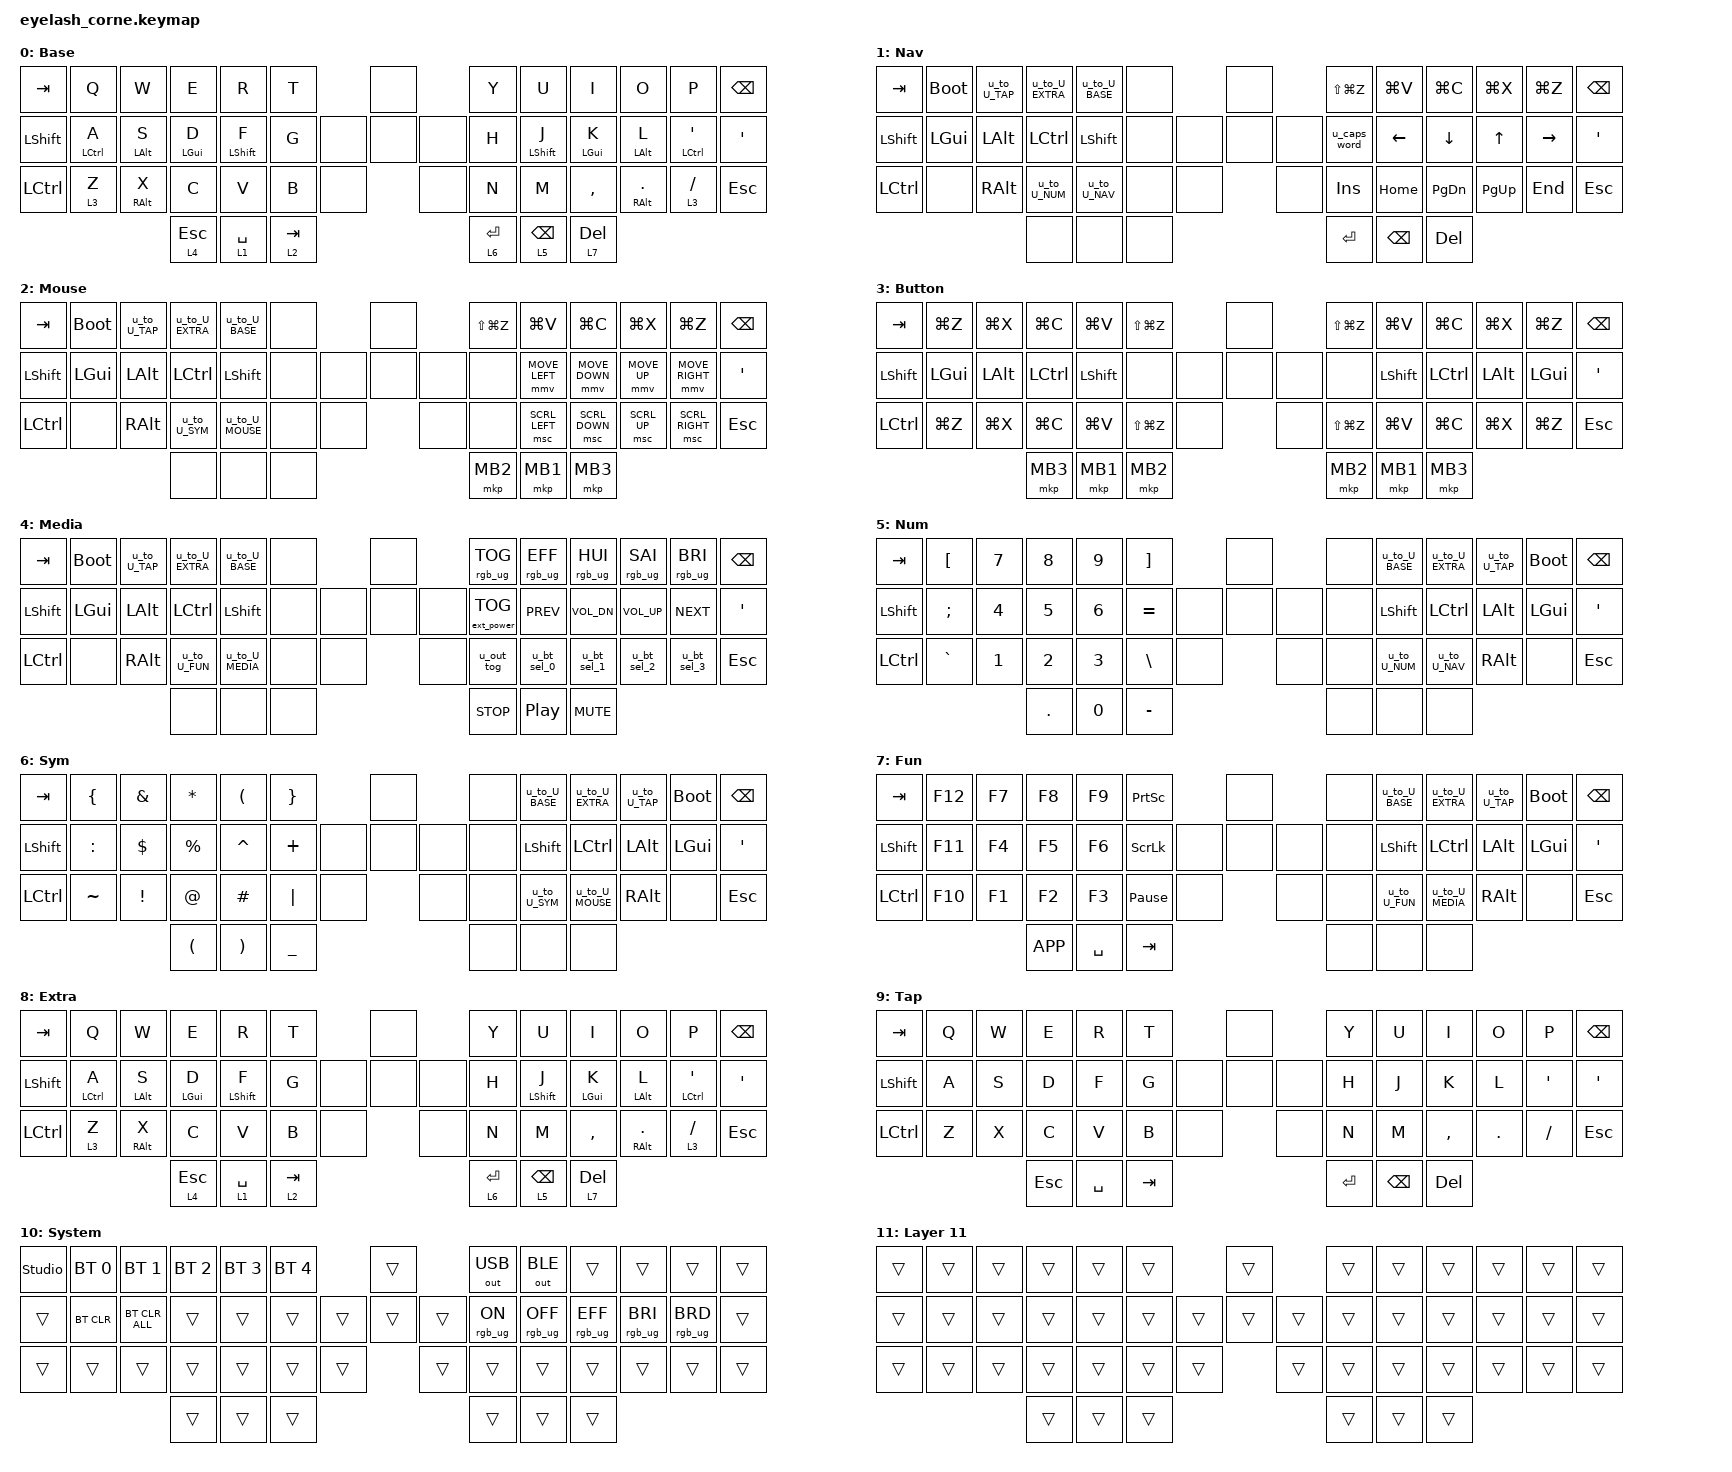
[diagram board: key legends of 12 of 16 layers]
// Derived from Manna Harbour Miryoku ZMK; explicit vendor keymap.

#define ZMK_POINTING_DEFAULT_MOVE_VAL 1200
#define ZMK_POINTING_DEFAULT_SCRL_VAL 25

#include <input/processors.dtsi>
#include <zephyr/dt-bindings/input/input-event-codes.h>
#include <behaviors/runtime-sensor-rotate.dtsi>
#include <behaviors.dtsi>
#include <dt-bindings/zmk/bt.h>
#include <dt-bindings/zmk/ext_power.h>
#include <dt-bindings/zmk/keys.h>
#include <dt-bindings/zmk/outputs.h>
#include <dt-bindings/zmk/pointing.h>
#include <dt-bindings/zmk/rgb.h>

&soft_off { hold-time-ms = <2000>; };

/ {
    behaviors {
        td0: td0 {
            compatible = "zmk,behavior-tap-dance";
            display-name = "Shift/Caps Lock Tap Dance";
            #binding-cells = <0>;
            bindings = <&kp LEFT_SHIFT>, <&kp CAPS>;
        };

        rsr_vol: rsr_vol {
            compatible = "zmk,behavior-runtime-sensor-rotate";
            #sensor-binding-cells = <0>;
            tap-ms = <5>;
            cw-binding = <&kp C_VOL_UP>;
            ccw-binding = <&kp C_VOL_DN>;
        };

        rsr_trans: rsr_trans {
            compatible = "zmk,behavior-runtime-sensor-rotate";
            #sensor-binding-cells = <0>;
            tap-ms = <0>;
        };
    };

    combos {
        compatible = "zmk,combos";

        softoff {
            bindings = <&soft_off>;
            key-positions = <1 15 29>;
        };
    };
};

/ {
    keymap {
        compatible = "zmk,keymap";

        BASE {
            display-name = "Base";
            bindings = <
&kp TAB    &kp Q         &kp W         &kp E          &kp R          &kp T                        &none         &kp Y        &kp U          &kp I          &kp O           &kp P           &kp BSPC
&kp LSHFT  &u_mt LCTRL A  &u_mt LALT S  &u_mt LGUI D  &u_mt LSHFT F  &kp G  &none  &none  &none  &kp H  &u_mt LSHFT J  &u_mt LGUI K  &u_mt LALT L  &u_mt LCTRL SQT  &kp SQT
&kp LCTRL  &u_lt 3 Z     &u_mt RALT X  &kp C          &kp V          &kp B        &none           &none         &kp N        &kp M          &kp COMMA      &u_mt RALT DOT  &u_lt 3 SLASH   &kp ESC
                                       &u_lt 4 ESC    &u_lt 1 SPACE  &u_lt 2 TAB                                &u_lt 6 RET  &u_lt 5 BSPC   &u_lt 7 DEL
            >;

            sensor-bindings = <&rsr_vol &rsr_trans>;
        };

        NAV {
            display-name = "Nav";
            bindings = <
&kp TAB    &bootloader  &u_to_U_TAP  &u_to_U_EXTRA  &u_to_U_BASE  &none                  &none         &kp LS(LG(Z))  &kp LG(V)  &kp LG(C)  &kp LG(X)  &kp LG(Z)  &kp BSPC
&kp LSHFT  &kp LGUI     &kp LALT     &kp LCTRL      &kp LSHFT     &none           &none  &none  &none  &u_caps_word   &kp LEFT   &kp DOWN   &kp UP     &kp RIGHT  &kp SQT
&kp LCTRL  &none        &kp RALT     &u_to_U_NUM    &u_to_U_NAV   &none  &none           &none         &kp INS        &kp HOME   &kp PG_DN  &kp PG_UP  &kp END    &kp ESC
                                     &none          &none         &none                                &kp RET        &kp BSPC   &kp DEL
            >;

            sensor-bindings = <&rsr_vol &rsr_trans>;
        };

        MOUSE {
            display-name = "Mouse";
            bindings = <
&kp TAB    &bootloader  &u_to_U_TAP  &u_to_U_EXTRA  &u_to_U_BASE   &none                  &none         &kp LS(LG(Z))  &kp LG(V)       &kp LG(C)       &kp LG(X)     &kp LG(Z)        &kp BSPC
&kp LSHFT  &kp LGUI     &kp LALT     &kp LCTRL      &kp LSHFT      &none           &none  &none  &none  &none          &mmv MOVE_LEFT  &mmv MOVE_DOWN  &mmv MOVE_UP  &mmv MOVE_RIGHT  &kp SQT
&kp LCTRL  &none        &kp RALT     &u_to_U_SYM    &u_to_U_MOUSE  &none  &none           &none         &none          &msc SCRL_LEFT  &msc SCRL_DOWN  &msc SCRL_UP  &msc SCRL_RIGHT  &kp ESC
                                     &none          &none          &none                                &mkp MB2       &mkp MB1        &mkp MB3
            >;

            sensor-bindings = <&rsr_vol &rsr_trans>;
        };

        BUTTON {
            display-name = "Button";
            bindings = <
&kp TAB    &kp LG(Z)  &kp LG(X)  &kp LG(C)  &kp LG(V)  &kp LS(LG(Z))                  &none         &kp LS(LG(Z))  &kp LG(V)  &kp LG(C)  &kp LG(X)  &kp LG(Z)  &kp BSPC
&kp LSHFT  &kp LGUI   &kp LALT   &kp LCTRL  &kp LSHFT  &none                   &none  &none  &none  &none          &kp LSHFT  &kp LCTRL  &kp LALT   &kp LGUI   &kp SQT
&kp LCTRL  &kp LG(Z)  &kp LG(X)  &kp LG(C)  &kp LG(V)  &kp LS(LG(Z))  &none           &none         &kp LS(LG(Z))  &kp LG(V)  &kp LG(C)  &kp LG(X)  &kp LG(Z)  &kp ESC
                                 &mkp MB3   &mkp MB1   &mkp MB2                                     &mkp MB2       &mkp MB1   &mkp MB3
            >;

            sensor-bindings = <&rsr_vol &rsr_trans>;
        };

        MEDIA {
            display-name = "Media";
            bindings = <
&kp TAB    &bootloader  &u_to_U_TAP  &u_to_U_EXTRA  &u_to_U_BASE   &none                  &none         &rgb_ug RGB_TOG    &rgb_ug RGB_EFF  &rgb_ug RGB_HUI  &rgb_ug RGB_SAI  &rgb_ug RGB_BRI  &kp BSPC
&kp LSHFT  &kp LGUI     &kp LALT     &kp LCTRL      &kp LSHFT      &none           &none  &none  &none  &ext_power EP_TOG  &kp C_PREV       &kp C_VOL_DN     &kp C_VOL_UP     &kp C_NEXT       &kp SQT
&kp LCTRL  &none        &kp RALT     &u_to_U_FUN    &u_to_U_MEDIA  &none  &none           &none         &u_out_tog         &u_bt_sel_0      &u_bt_sel_1      &u_bt_sel_2      &u_bt_sel_3      &kp ESC
                                     &none          &none          &none                                &kp C_STOP         &kp C_PP         &kp C_MUTE
            >;

            sensor-bindings = <&rsr_vol &rsr_trans>;
        };

        NUM {
            display-name = "Num";
            bindings = <
&kp TAB    &kp LBKT   &kp N7  &kp N8   &kp N9  &kp RBKT                   &none         &none  &u_to_U_BASE  &u_to_U_EXTRA  &u_to_U_TAP  &bootloader  &kp BSPC
&kp LSHFT  &kp SEMI   &kp N4  &kp N5   &kp N6  &kp EQUAL           &none  &none  &none  &none  &kp LSHFT     &kp LCTRL      &kp LALT     &kp LGUI     &kp SQT
&kp LCTRL  &kp GRAVE  &kp N1  &kp N2   &kp N3  &kp BSLH   &none           &none         &none  &u_to_U_NUM   &u_to_U_NAV    &kp RALT     &none        &kp ESC
                              &kp DOT  &kp N0  &kp MINUS                                &none  &none         &none
            >;

            sensor-bindings = <&rsr_vol &rsr_trans>;
        };

        SYM {
            display-name = "Sym";
            bindings = <
&kp TAB    &kp LBRC   &kp AMPS  &kp ASTRK  &kp LPAR   &kp RBRC                   &none         &none  &u_to_U_BASE  &u_to_U_EXTRA  &u_to_U_TAP  &bootloader  &kp BSPC
&kp LSHFT  &kp COLON  &kp DLLR  &kp PRCNT  &kp CARET  &kp PLUS            &none  &none  &none  &none  &kp LSHFT     &kp LCTRL      &kp LALT     &kp LGUI     &kp SQT
&kp LCTRL  &kp TILDE  &kp EXCL  &kp AT     &kp HASH   &kp PIPE   &none           &none         &none  &u_to_U_SYM   &u_to_U_MOUSE  &kp RALT     &none        &kp ESC
                                &kp LPAR   &kp RPAR   &kp UNDER                                &none  &none         &none
            >;

            sensor-bindings = <&rsr_vol &rsr_trans>;
        };

        FUN {
            display-name = "Fun";
            bindings = <
&kp TAB    &kp F12  &kp F7  &kp F8     &kp F9     &kp PSCRN                        &none         &none  &u_to_U_BASE  &u_to_U_EXTRA  &u_to_U_TAP  &bootloader  &kp BSPC
&kp LSHFT  &kp F11  &kp F4  &kp F5     &kp F6     &kp SLCK                  &none  &none  &none  &none  &kp LSHFT     &kp LCTRL      &kp LALT     &kp LGUI     &kp SQT
&kp LCTRL  &kp F10  &kp F1  &kp F2     &kp F3     &kp PAUSE_BREAK  &none           &none         &none  &u_to_U_FUN   &u_to_U_MEDIA  &kp RALT     &none        &kp ESC
                            &kp K_APP  &kp SPACE  &kp TAB                                        &none  &none         &none
            >;

            sensor-bindings = <&rsr_vol &rsr_trans>;
        };

        EXTRA {
            display-name = "Extra";
            bindings = <
&kp TAB    &kp Q         &kp W         &kp E          &kp R          &kp T                        &none         &kp Y        &kp U          &kp I          &kp O           &kp P           &kp BSPC
&kp LSHFT  &u_mt LCTRL A  &u_mt LALT S  &u_mt LGUI D  &u_mt LSHFT F  &kp G  &none  &none  &none  &kp H  &u_mt LSHFT J  &u_mt LGUI K  &u_mt LALT L  &u_mt LCTRL SQT  &kp SQT
&kp LCTRL  &u_lt 3 Z     &u_mt RALT X  &kp C          &kp V          &kp B        &none           &none         &kp N        &kp M          &kp COMMA      &u_mt RALT DOT  &u_lt 3 SLASH   &kp ESC
                                       &u_lt 4 ESC    &u_lt 1 SPACE  &u_lt 2 TAB                                &u_lt 6 RET  &u_lt 5 BSPC   &u_lt 7 DEL
            >;

            sensor-bindings = <&rsr_vol &rsr_trans>;
        };

        TAP {
            display-name = "Tap";
            bindings = <
&kp TAB    &kp Q  &kp W  &kp E    &kp R      &kp T                    &none         &kp Y    &kp U     &kp I      &kp O    &kp P      &kp BSPC
&kp LSHFT  &kp A  &kp S  &kp D    &kp F      &kp G             &none  &none  &none  &kp H    &kp J     &kp K      &kp L    &kp SQT    &kp SQT
&kp LCTRL  &kp Z  &kp X  &kp C    &kp V      &kp B    &none           &none         &kp N    &kp M     &kp COMMA  &kp DOT  &kp SLASH  &kp ESC
                         &kp ESC  &kp SPACE  &kp TAB                                &kp RET  &kp BSPC  &kp DEL
            >;

            sensor-bindings = <&rsr_vol &rsr_trans>;
        };
    };
};

/ {
    macros {
        u_macro_u_bt_sel_0: u_macro_u_bt_sel_0 {
            compatible = "zmk,behavior-macro";
            #binding-cells = <0>;
            wait-ms = <0>;
            bindings = <&bt BT_SEL 0 &bt BT_CLR>;
        };
    };
};

/ {
    behaviors {
        u_bt_sel_0: u_bt_sel_0 {
            compatible = "zmk,behavior-mod-morph";
            #binding-cells = <0>;
            bindings = <&bt BT_SEL 0>, <&u_macro_u_bt_sel_0>;

            mods = <(MOD_LSFT|MOD_RSFT)>;
        };
    };
};

/ {
    macros {
        u_macro_u_bt_sel_1: u_macro_u_bt_sel_1 {
            compatible = "zmk,behavior-macro";
            #binding-cells = <0>;
            wait-ms = <0>;
            bindings = <&bt BT_SEL 1 &bt BT_CLR>;
        };
    };
};

/ {
    behaviors {
        u_bt_sel_1: u_bt_sel_1 {
            compatible = "zmk,behavior-mod-morph";
            #binding-cells = <0>;
            bindings = <&bt BT_SEL 1>, <&u_macro_u_bt_sel_1>;

            mods = <(MOD_LSFT|MOD_RSFT)>;
        };
    };
};

/ {
    macros {
        u_macro_u_bt_sel_2: u_macro_u_bt_sel_2 {
            compatible = "zmk,behavior-macro";
            #binding-cells = <0>;
            wait-ms = <0>;
            bindings = <&bt BT_SEL 2 &bt BT_CLR>;
        };
    };
};

/ {
    behaviors {
        u_bt_sel_2: u_bt_sel_2 {
            compatible = "zmk,behavior-mod-morph";
            #binding-cells = <0>;
            bindings = <&bt BT_SEL 2>, <&u_macro_u_bt_sel_2>;

            mods = <(MOD_LSFT|MOD_RSFT)>;
        };
    };
};

/ {
    macros {
        u_macro_u_bt_sel_3: u_macro_u_bt_sel_3 {
            compatible = "zmk,behavior-macro";
            #binding-cells = <0>;
            wait-ms = <0>;
            bindings = <&bt BT_SEL 3 &bt BT_CLR>;
        };
    };
};

/ {
    behaviors {
        u_bt_sel_3: u_bt_sel_3 {
            compatible = "zmk,behavior-mod-morph";
            #binding-cells = <0>;
            bindings = <&bt BT_SEL 3>, <&u_macro_u_bt_sel_3>;

            mods = <(MOD_LSFT|MOD_RSFT)>;
        };
    };
};

/ {
    macros {
        u_macro_u_bt_sel_4: u_macro_u_bt_sel_4 {
            compatible = "zmk,behavior-macro";
            #binding-cells = <0>;
            wait-ms = <0>;
            bindings = <&bt BT_SEL 4 &bt BT_CLR>;
        };
    };
};

/ {
    behaviors {
        u_bt_sel_4: u_bt_sel_4 {
            compatible = "zmk,behavior-mod-morph";
            #binding-cells = <0>;
            bindings = <&bt BT_SEL 4>, <&u_macro_u_bt_sel_4>;

            mods = <(MOD_LSFT|MOD_RSFT)>;
        };
    };
};

/ {
    behaviors {
        u_out_tog: u_out_tog {
            compatible = "zmk,behavior-mod-morph";
            #binding-cells = <0>;
            bindings = <&out OUT_TOG>, <&out OUT_USB>;

            mods = <(MOD_LSFT|MOD_RSFT)>;
        };
    };
};

/ {
    behaviors {
        u_caps_word: u_caps_word {
            compatible = "zmk,behavior-mod-morph";
            #binding-cells = <0>;
            bindings = <&caps_word>, <&kp CAPS>;

            mods = <(MOD_LSFT|MOD_RSFT)>;
        };
    };
};

/ {
    behaviors {
        u_to_U_BASE: u_to_U_BASE {
            compatible = "zmk,behavior-tap-dance";
            #binding-cells = <0>;
            tapping-term-ms = <200>;
            bindings = <&none>, <&to 0>;
        };
    };
};

/ {
    behaviors {
        u_to_U_EXTRA: u_to_U_EXTRA {
            compatible = "zmk,behavior-tap-dance";
            #binding-cells = <0>;
            tapping-term-ms = <200>;
            bindings = <&none>, <&to 8>;
        };
    };
};

/ {
    behaviors {
        u_to_U_TAP: u_to_U_TAP {
            compatible = "zmk,behavior-tap-dance";
            #binding-cells = <0>;
            tapping-term-ms = <200>;
            bindings = <&none>, <&to 9>;
        };
    };
};

/ {
    behaviors {
        u_to_U_BUTTON: u_to_U_BUTTON {
            compatible = "zmk,behavior-tap-dance";
            #binding-cells = <0>;
            tapping-term-ms = <200>;
            bindings = <&none>, <&to 3>;
        };
    };
};

/ {
    behaviors {
        u_to_U_NAV: u_to_U_NAV {
            compatible = "zmk,behavior-tap-dance";
            #binding-cells = <0>;
            tapping-term-ms = <200>;
            bindings = <&none>, <&to 1>;
        };
    };
};

/ {
    behaviors {
        u_to_U_MOUSE: u_to_U_MOUSE {
            compatible = "zmk,behavior-tap-dance";
            #binding-cells = <0>;
            tapping-term-ms = <200>;
            bindings = <&none>, <&to 2>;
        };
    };
};

/ {
    behaviors {
        u_to_U_MEDIA: u_to_U_MEDIA {
            compatible = "zmk,behavior-tap-dance";
            #binding-cells = <0>;
            tapping-term-ms = <200>;
            bindings = <&none>, <&to 4>;
        };
    };
};

/ {
    behaviors {
        u_to_U_NUM: u_to_U_NUM {
            compatible = "zmk,behavior-tap-dance";
            #binding-cells = <0>;
            tapping-term-ms = <200>;
            bindings = <&none>, <&to 5>;
        };
    };
};

/ {
    behaviors {
        u_to_U_SYM: u_to_U_SYM {
            compatible = "zmk,behavior-tap-dance";
            #binding-cells = <0>;
            tapping-term-ms = <200>;
            bindings = <&none>, <&to 6>;
        };
    };
};

/ {
    behaviors {
        u_to_U_FUN: u_to_U_FUN {
            compatible = "zmk,behavior-tap-dance";
            #binding-cells = <0>;
            tapping-term-ms = <200>;
            bindings = <&none>, <&to 7>;
        };
    };
};

&mmv {
    acceleration-exponent = <1>;
    time-to-max-speed-ms = <1500>;
    delay-ms = <0>;
};

/ {
    behaviors {
        u_mt: u_mt {
            compatible = "zmk,behavior-hold-tap";
            #binding-cells = <2>;
            tapping-term-ms = <280>;
            quick-tap-ms = <175>;
            require-prior-idle-ms = <150>;
            flavor = "balanced";
            bindings = <&kp>, <&kp>;
        };

        u_lt: u_lt {
            compatible = "zmk,behavior-hold-tap";
            #binding-cells = <2>;
            tapping-term-ms = <200>;
            flavor = "tap-preferred";
            bindings = <&mo>, <&kp>;
        };
    };
};

/ {
    combos {
        miryoku_system {
            bindings = <&mo 10>;
            key-positions = <42 47>;
            timeout-ms = <50>;
        };
    };

    keymap {
        layer_10 {
            display-name = "System";
            bindings = <
            &studio_unlock &bt BT_SEL 0 &bt BT_SEL 1 &bt BT_SEL 2 &bt BT_SEL 3 &bt BT_SEL 4 &trans &out OUT_USB &out OUT_BLE &trans &trans &trans &trans
            &trans &bt BT_CLR &bt BT_CLR_ALL &trans &trans &trans &trans &trans &trans &rgb_ug RGB_ON &rgb_ug RGB_OFF &rgb_ug RGB_EFF &rgb_ug RGB_BRI &rgb_ug RGB_BRD &trans
            &trans &trans &trans &trans &trans &trans &trans &trans &trans &trans &trans &trans &trans &trans
            &trans &trans &trans &trans &trans &trans
            >;

            sensor-bindings = <&rsr_vol &rsr_trans>;
        };

        layer_11 {
            display-name = "Layer 11";
            bindings = <
            &trans &trans &trans &trans &trans &trans &trans &trans &trans &trans &trans &trans &trans
            &trans &trans &trans &trans &trans &trans &trans &trans &trans &trans &trans &trans &trans &trans &trans
            &trans &trans &trans &trans &trans &trans &trans &trans &trans &trans &trans &trans &trans &trans
            &trans &trans &trans &trans &trans &trans
            >;

            sensor-bindings = <&rsr_vol &rsr_trans>;
        };

        layer_12 {
            display-name = "Layer 12";
            bindings = <
            &trans &trans &trans &trans &trans &trans &trans &trans &trans &trans &trans &trans &trans
            &trans &trans &trans &trans &trans &trans &trans &trans &trans &trans &trans &trans &trans &trans &trans
            &trans &trans &trans &trans &trans &trans &trans &trans &trans &trans &trans &trans &trans &trans
            &trans &trans &trans &trans &trans &trans
            >;

            sensor-bindings = <&rsr_vol &rsr_trans>;
        };

        layer_13 {
            display-name = "Layer 13";
            bindings = <
            &trans &trans &trans &trans &trans &trans &trans &trans &trans &trans &trans &trans &trans
            &trans &trans &trans &trans &trans &trans &trans &trans &trans &trans &trans &trans &trans &trans &trans
            &trans &trans &trans &trans &trans &trans &trans &trans &trans &trans &trans &trans &trans &trans
            &trans &trans &trans &trans &trans &trans
            >;

            sensor-bindings = <&rsr_vol &rsr_trans>;
        };

        layer_14 {
            display-name = "Layer 14";
            bindings = <
            &trans &trans &trans &trans &trans &trans &trans &trans &trans &trans &trans &trans &trans
            &trans &trans &trans &trans &trans &trans &trans &trans &trans &trans &trans &trans &trans &trans &trans
            &trans &trans &trans &trans &trans &trans &trans &trans &trans &trans &trans &trans &trans &trans
            &trans &trans &trans &trans &trans &trans
            >;

            sensor-bindings = <&rsr_vol &rsr_trans>;
        };

        layer_15 {
            display-name = "Layer 15";
            bindings = <
            &trans &trans &trans &trans &trans &trans &trans &trans &trans &trans &trans &trans &trans
            &trans &trans &trans &trans &trans &trans &trans &trans &trans &trans &trans &trans &trans &trans &trans
            &trans &trans &trans &trans &trans &trans &trans &trans &trans &trans &trans &trans &trans &trans
            &trans &trans &trans &trans &trans &trans
            >;

            sensor-bindings = <&rsr_vol &rsr_trans>;
        };
    };
};
